# OCP2SCP1 register map
Vendor: Texas Instruments
Peripheral module from a debugger description file (folder omap5430_ES2_PUBLIC).
Registers are 32-bit, read-only, reset 0x1 unless marked. A register's access mark holds for its fields unless they carry their own. Offsets are as the file gives them; lines under a group give offsets from that group; [hi:lo] are bit positions; {n}, {i} and the like mark numbered series; 'fields as' and 'values as' point back to an identical list; <NAME> marks a mode.

## OCP2SCP1
0x00 OCP2SCP_REVISION reset not defined — IP Revision Identifier (X.Y.R)
  [31:0] REVISION — IP Revision
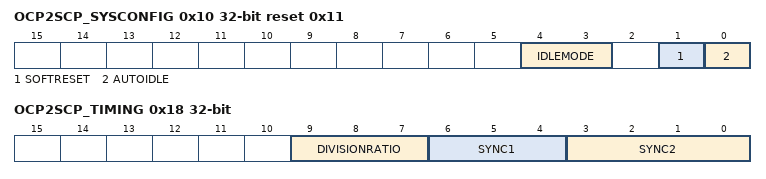
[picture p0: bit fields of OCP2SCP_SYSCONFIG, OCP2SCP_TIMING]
0x10 OCP2SCP_SYSCONFIG access per field reset 0x11 — SYSTEM CONFIGURATION REGISTER
  [4:3] IDLEMODE rw — enum=Reserved .
    0=Force Idle mode. An idle request is acknowledged unconditionally.; 1=No Idle mode. An idle request is never acknowledged.; 2=Reserved (Smart Idle mode. The acknowledgement to an idle request is given based on the internal activity.); 3=SmartIdle (Reserved)
  [1] SOFTRESET rw — Software Reset. Set this bit to 1 to trigger a module reset. The bit is automatically reset by the hardware. During reads, it always returns 0.
    0=Normal Mode; 1=Reset (The module is reset.)
  [0] AUTOIDLE rw — L4-interconnect interface clock gating control.
    0=FreeRun (Internal L4-interconnect interface clock is free-running); 1=Automatic internal L4-interconnect interface clock gating, based on the L4-interconnect interface activity
0x14 OCP2SCP_SYSSTATUS — System Status register.
  [0] RESETDONE
    1=Complete (Reset completed); 0=InProgress (Internal Reset is on-going)
0x18 OCP2SCP_TIMING access per field — Interrupt Status Register (legacy) for first line of interrupt.
  [9:7] DIVISIONRATIO rw — Division Ration of the SCP clock in relation to OCP input clock.
  [6:4] SYNC1 rw — Number of SCPclock cycles defining SYNC1
  [3:0] SYNC2 rw — Number of SCPclock cycles defining SYNC2
